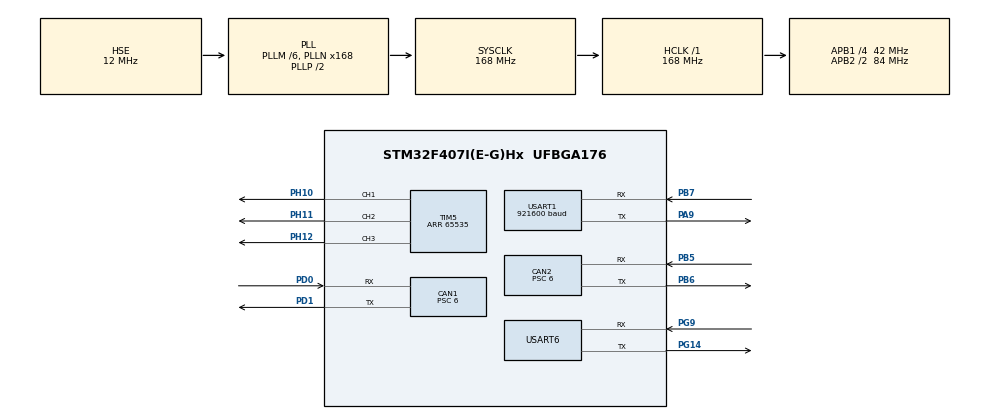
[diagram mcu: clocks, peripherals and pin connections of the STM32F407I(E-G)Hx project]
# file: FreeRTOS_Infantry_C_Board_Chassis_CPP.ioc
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CAN1.BS1=CAN_BS1_5TQ
CAN1.CalculateBaudRate=1000000
CAN1.CalculateTimeBit=1000
CAN1.CalculateTimeQuantum=142.85714285714286
CAN1.Prescaler=6
CAN2.BS1=CAN_BS1_5TQ
CAN2.CalculateBaudRate=1000000
CAN2.CalculateTimeBit=1000
CAN2.CalculateTimeQuantum=142.85714285714286
CAN2.NART=ENABLE
CAN2.Prescaler=6
Dma.Request0=USART1_RX
Dma.Request1=USART1_TX
Dma.Request2=USART6_RX
Dma.Request3=USART6_TX
Dma.USART1_RX.0.Direction=DMA_PERIPH_TO_MEMORY
Dma.USART1_RX.0.FIFOMode=DMA_FIFOMODE_DISABLE
Dma.USART1_RX.0.Instance=DMA2_Stream2
Dma.USART1_RX.0.MemDataAlignment=DMA_MDATAALIGN_BYTE
Dma.USART1_RX.0.MemInc=DMA_MINC_ENABLE
Dma.USART1_RX.0.Mode=DMA_NORMAL
Dma.USART1_RX.0.PeriphDataAlignment=DMA_PDATAALIGN_BYTE
Dma.USART1_RX.0.PeriphInc=DMA_PINC_DISABLE
Dma.USART1_RX.0.Priority=DMA_PRIORITY_LOW
Dma.USART1_TX.1.Direction=DMA_MEMORY_TO_PERIPH
Dma.USART1_TX.1.FIFOMode=DMA_FIFOMODE_DISABLE
Dma.USART1_TX.1.Instance=DMA2_Stream7
Dma.USART1_TX.1.MemDataAlignment=DMA_MDATAALIGN_BYTE
Dma.USART1_TX.1.MemInc=DMA_MINC_ENABLE
Dma.USART1_TX.1.Mode=DMA_NORMAL
Dma.USART1_TX.1.PeriphDataAlignment=DMA_PDATAALIGN_BYTE
Dma.USART1_TX.1.PeriphInc=DMA_PINC_DISABLE
Dma.USART1_TX.1.Priority=DMA_PRIORITY_LOW
Dma.USART6_RX.2.Direction=DMA_PERIPH_TO_MEMORY
Dma.USART6_RX.2.FIFOMode=DMA_FIFOMODE_DISABLE
Dma.USART6_RX.2.Instance=DMA2_Stream1
Dma.USART6_RX.2.MemDataAlignment=DMA_MDATAALIGN_BYTE
Dma.USART6_RX.2.MemInc=DMA_MINC_ENABLE
Dma.USART6_RX.2.Mode=DMA_NORMAL
Dma.USART6_RX.2.PeriphDataAlignment=DMA_PDATAALIGN_BYTE
Dma.USART6_RX.2.PeriphInc=DMA_PINC_DISABLE
Dma.USART6_RX.2.Priority=DMA_PRIORITY_LOW
Dma.USART6_TX.3.Direction=DMA_MEMORY_TO_PERIPH
Dma.USART6_TX.3.FIFOMode=DMA_FIFOMODE_DISABLE
Dma.USART6_TX.3.Instance=DMA2_Stream6
Dma.USART6_TX.3.MemDataAlignment=DMA_MDATAALIGN_BYTE
Dma.USART6_TX.3.MemInc=DMA_MINC_ENABLE
Dma.USART6_TX.3.Mode=DMA_NORMAL
Dma.USART6_TX.3.PeriphDataAlignment=DMA_PDATAALIGN_BYTE
Dma.USART6_TX.3.PeriphInc=DMA_PINC_DISABLE
Dma.USART6_TX.3.Priority=DMA_PRIORITY_LOW
FREERTOS.Tasks01=defaultTask,8,128,StartDefaultTask,Default,NULL,Dynamic,NULL,NULL;chassisTask,40,128,ChassisTask,As external,NULL,Dynamic,NULL,NULL;capacityAskTask,32,128,CapacityAskTask,As external,NULL,Dynamic,NULL,NULL;uiTask,24,128,UITask,As external,NULL,Dynamic,NULL,NULL;refereeDetect,24,128,RefereeDetectTask,As external,NULL,Dynamic,NULL,NULL;communicationTa,40,512,CommunicationTask,As external,NULL,Dynamic,NULL,NULL;errorHandleTask,16,128,ErrorHandleTask,As external,NULL,Dynamic,NULL,NULL;capacityChargeT,33,128,CapacityChargeTask,As external,NULL,Dynamic,NULL,NULL;rlsTask,16,1024,RlsTask,As external,NULL,Dynamic,NULL,NULL
Mcu.Family=STM32F4
Mcu.Name=STM32F407I(E-G)Hx
Mcu.Package=UFBGA176
NVIC.CAN1_RX0_IRQn=true\:0\:0\:true\:false\:true\:false\:true\:true\:true
NVIC.CAN2_RX0_IRQn=true\:4\:0\:true\:false\:true\:false\:true\:true\:true
NVIC.DMA2_Stream1_IRQn=true\:3\:0\:true\:false\:true\:false\:false\:true\:true
NVIC.DMA2_Stream2_IRQn=true\:4\:0\:true\:false\:true\:false\:false\:true\:true
NVIC.DMA2_Stream6_IRQn=true\:4\:0\:true\:false\:true\:false\:false\:true\:true
NVIC.DMA2_Stream7_IRQn=true\:4\:0\:true\:false\:true\:false\:false\:true\:true
NVIC.PriorityGroup=NVIC_PRIORITYGROUP_4
NVIC.TIM6_DAC_IRQn=true\:15\:0\:false\:false\:true\:false\:false\:true\:true
NVIC.TIM7_IRQn=true\:1\:0\:true\:false\:true\:false\:true\:true\:true
NVIC.TimeBase=TIM6_DAC_IRQn
NVIC.TimeBaseIP=TIM6
NVIC.USART1_IRQn=true\:4\:0\:true\:false\:true\:false\:false\:true\:true
NVIC.USART6_IRQn=true\:3\:0\:true\:false\:true\:false\:false\:true\:true
PA13.Mode=Serial_Wire
PA13.Signal=SYS_JTMS-SWDIO
PA14.Mode=Serial_Wire
PA14.Signal=SYS_JTCK-SWCLK
PA9.Mode=Asynchronous
PA9.Signal=USART1_TX
PB5.Mode=CAN_Activate
PB5.Signal=CAN2_RX
PB6.Mode=CAN_Activate
PB6.Signal=CAN2_TX
PB7.Mode=Asynchronous
PB7.Signal=USART1_RX
PD0.Mode=CAN_Activate
PD0.Signal=CAN1_RX
PD1.Mode=CAN_Activate
PD1.Signal=CAN1_TX
PG14.Mode=Asynchronous
PG14.Signal=USART6_TX
PG9.Mode=Asynchronous
PG9.Signal=USART6_RX
PH0-OSC_IN.Mode=HSE-External-Oscillator
PH0-OSC_IN.Signal=RCC_OSC_IN
PH1-OSC_OUT.Mode=HSE-External-Oscillator
PH1-OSC_OUT.Signal=RCC_OSC_OUT
PH10.Signal=S_TIM5_CH1
PH11.Signal=S_TIM5_CH2
PH12.Signal=S_TIM5_CH3
ProjectManager.HeapSize=0x200
ProjectManager.StackSize=0x400
ProjectManager.TargetToolchain=MDK-ARM V5.32
RCC.48MHZClocksFreq_Value=84000000
RCC.AHBFreq_Value=168000000
RCC.APB1CLKDivider=RCC_HCLK_DIV4
RCC.APB1Freq_Value=42000000
RCC.APB1TimFreq_Value=84000000
RCC.APB2CLKDivider=RCC_HCLK_DIV2
RCC.APB2Freq_Value=84000000
RCC.APB2TimFreq_Value=168000000
RCC.CortexFreq_Value=168000000
RCC.HCLKFreq_Value=168000000
RCC.HSE_VALUE=12000000
RCC.HSI_VALUE=16000000
RCC.LSE_VALUE=32768
RCC.PLLM=6
RCC.PLLN=168
RCC.PLLSourceVirtual=RCC_PLLSOURCE_HSE
RCC.SYSCLKFreq_VALUE=168000000
RCC.SYSCLKSource=RCC_SYSCLKSOURCE_PLLCLK
RCC.VCOOutputFreq_Value=336000000
SH.S_TIM5_CH1.0=TIM5_CH1,PWM Generation1 CH1
SH.S_TIM5_CH2.0=TIM5_CH2,PWM Generation2 CH2
SH.S_TIM5_CH3.0=TIM5_CH3,PWM Generation3 CH3
TIM5.Channel-PWM\ Generation1\ CH1=TIM_CHANNEL_1
TIM5.Channel-PWM\ Generation2\ CH2=TIM_CHANNEL_2
TIM5.Channel-PWM\ Generation3\ CH3=TIM_CHANNEL_3
TIM5.Period=65535
TIM5.Pulse-PWM\ Generation1\ CH1=10000
TIM5.Pulse-PWM\ Generation2\ CH2=10000
TIM5.Pulse-PWM\ Generation3\ CH3=10000
TIM7.Period=1000-1
TIM7.Prescaler=84-1
USART1.BaudRate=921600
USART1.VirtualMode=VM_ASYNC
USART6.VirtualMode=VM_ASYNC
VP_FREERTOS_VS_CMSIS_V2.Mode=CMSIS_V2
VP_SYS_VS_tim6.Mode=TIM6
VP_TIM5_VS_ClockSourceINT.Mode=Internal
VP_TIM7_VS_ClockSourceINT.Mode=Enable_Timer
board=custom

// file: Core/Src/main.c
/* USER CODE BEGIN Header */
/**
  ******************************************************************************
  * @file           : main.c
  * @brief          : Main program body
  ******************************************************************************
  * @attention
  *
  * Copyright (c) 2024 STMicroelectronics.
  * All rights reserved.
  *
  * This software is licensed under terms that can be found in the LICENSE file
  * in the root directory of this software component.
  * If no LICENSE file comes with this software, it is provided AS-IS.
  *
  ******************************************************************************
  */
/* USER CODE END Header */
#include "main.h"
#include "cmsis_os.h"
#include "can.h"
#include "dma.h"
#include "tim.h"
#include "usart.h"
#include "gpio.h"

void SystemClock_Config(void);
void MX_FREERTOS_Init(void);
/* USER CODE BEGIN PFP */
void init();
void MainCallBack();
/* USER CODE END PFP */

int main(void)
{

  /* MCU Configuration--------------------------------------------------------*/

  /* Reset of all peripherals, Initializes the Flash interface and the Systick. */
  HAL_Init();

  /* Configure the system clock */
  SystemClock_Config();

  /* Initialize all configured peripherals */
  MX_GPIO_Init();
  MX_DMA_Init();
  MX_CAN1_Init();
  MX_CAN2_Init();
  MX_TIM7_Init();
  MX_USART1_UART_Init();
  MX_USART6_UART_Init();
  MX_TIM5_Init();
  /* USER CODE BEGIN 2 */
  init();
  /* USER CODE END 2 */

  /* Init scheduler */
  osKernelInitialize();

  /* Call init function for freertos objects (in cmsis_os2.c) */
  MX_FREERTOS_Init();

  /* Start scheduler */
  osKernelStart();

  /* We should never get here as control is now taken by the scheduler */

  /* Infinite loop */
  while (1)
  {

  }
}

void SystemClock_Config(void)
{
  RCC_OscInitTypeDef RCC_OscInitStruct = {0};
  RCC_ClkInitTypeDef RCC_ClkInitStruct = {0};

  /** Configure the main internal regulator output voltage
  */
  __HAL_RCC_PWR_CLK_ENABLE();
  __HAL_PWR_VOLTAGESCALING_CONFIG(PWR_REGULATOR_VOLTAGE_SCALE1);

  /** Initializes the RCC Oscillators according to the specified parameters
  * in the RCC_OscInitTypeDef structure.
  */
  RCC_OscInitStruct.OscillatorType = RCC_OSCILLATORTYPE_HSE;
  RCC_OscInitStruct.HSEState = RCC_HSE_ON;
  RCC_OscInitStruct.PLL.PLLState = RCC_PLL_ON;
  RCC_OscInitStruct.PLL.PLLSource = RCC_PLLSOURCE_HSE;
  RCC_OscInitStruct.PLL.PLLM = 6;
  RCC_OscInitStruct.PLL.PLLN = 168;
  RCC_OscInitStruct.PLL.PLLP = RCC_PLLP_DIV2;
  RCC_OscInitStruct.PLL.PLLQ = 4;
  if (HAL_RCC_OscConfig(&RCC_OscInitStruct) != HAL_OK)
  {
    Error_Handler();
  }

  /** Initializes the CPU, AHB and APB buses clocks
  */
  RCC_ClkInitStruct.ClockType = RCC_CLOCKTYPE_HCLK|RCC_CLOCKTYPE_SYSCLK
                              |RCC_CLOCKTYPE_PCLK1|RCC_CLOCKTYPE_PCLK2;
  RCC_ClkInitStruct.SYSCLKSource = RCC_SYSCLKSOURCE_PLLCLK;
  RCC_ClkInitStruct.AHBCLKDivider = RCC_SYSCLK_DIV1;
  RCC_ClkInitStruct.APB1CLKDivider = RCC_HCLK_DIV4;
  RCC_ClkInitStruct.APB2CLKDivider = RCC_HCLK_DIV2;

  if (HAL_RCC_ClockConfig(&RCC_ClkInitStruct, FLASH_LATENCY_5) != HAL_OK)
  {
    Error_Handler();
  }
}

void HAL_TIM_PeriodElapsedCallback(TIM_HandleTypeDef *htim)
{
  if (htim->Instance == TIM6)
  {
    HAL_IncTick();
  }
  /* USER CODE BEGIN Callback 1 */
  else if (htim->Instance == TIM7) {
    MainCallBack();
  }
  /* USER CODE END Callback 1 */
}

void Error_Handler(void)
{
  __disable_irq();
  while (1)
  {
  }
}

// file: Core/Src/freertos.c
/* USER CODE BEGIN Header */
/**
  ******************************************************************************
  * File Name          : freertos.c
  * Description        : Code for freertos applications
  ******************************************************************************
  * @attention
  *
  * Copyright (c) 2024 STMicroelectronics.
  * All rights reserved.
  *
  * This software is licensed under terms that can be found in the LICENSE file
  * in the root directory of this software component.
  * If no LICENSE file comes with this software, it is provided AS-IS.
  *
  ******************************************************************************
  */
/* USER CODE END Header */

#include "FreeRTOS.h"
#include "task.h"
#include "main.h"
#include "cmsis_os.h"

/* Definitions for defaultTask */
osThreadId_t defaultTaskHandle;
const osThreadAttr_t defaultTask_attributes = {
  .name = "defaultTask",
  .stack_size = 128 * 4,
  .priority = (osPriority_t) osPriorityLow,
};
/* Definitions for chassisTask */
osThreadId_t chassisTaskHandle;
const osThreadAttr_t chassisTask_attributes = {
  .name = "chassisTask",
  .stack_size = 1024 * 4,
  .priority = (osPriority_t) osPriorityNormal,
};
/* Definitions for capacityAskTask */
osThreadId_t capacityAskTaskHandle;
const osThreadAttr_t capacityAskTask_attributes = {
  .name = "capacityAskTask",
  .stack_size = 128 * 4,
  .priority = (osPriority_t) osPriorityAboveNormal,
};
/* Definitions for uiTask */
osThreadId_t uiTaskHandle;
const osThreadAttr_t uiTask_attributes = {
  .name = "uiTask",
  .stack_size = 128 * 4,
  .priority = (osPriority_t) osPriorityNormal,
};
/* Definitions for refereeDetect */
osThreadId_t refereeDetectHandle;
const osThreadAttr_t refereeDetect_attributes = {
  .name = "refereeDetect",
  .stack_size = 128 * 4,
  .priority = (osPriority_t) osPriorityNormal,
};
/* Definitions for communicationTa */
osThreadId_t communicationTaHandle;
const osThreadAttr_t communicationTa_attributes = {
  .name = "communicationTa",
  .stack_size = 1024 * 4,
  .priority = (osPriority_t) osPriorityNormal,
};
/* Definitions for errorHandleTask */
osThreadId_t errorHandleTaskHandle;
const osThreadAttr_t errorHandleTask_attributes = {
  .name = "errorHandleTask",
  .stack_size = 128 * 4,
  .priority = (osPriority_t) osPriorityBelowNormal,
};
/* Definitions for capacityChargeT */
osThreadId_t capacityChargeTHandle;
const osThreadAttr_t capacityChargeT_attributes = {
  .name = "capacityChargeT",
  .stack_size = 128 * 4,
  .priority = (osPriority_t) osPriorityAboveNormal1,
};
/* Definitions for rlsTask */
osThreadId_t rlsTaskHandle;
const osThreadAttr_t rlsTask_attributes = {
  .name = "rlsTask",
  .stack_size = 1024 * 4,
  .priority = (osPriority_t) osPriorityBelowNormal,
};

void StartDefaultTask(void *argument);
extern void ChassisTask(void *argument);
extern void CapacityAskTask(void *argument);
//extern void UITask(void *argument);
//extern void RefereeDetectTask(void *argument);
extern void CommunicationTask(void *argument);
extern void ErrorHandleTask(void *argument);
extern void CapacityChargeTask(void *argument);
extern void RlsTask(void *argument);

void MX_FREERTOS_Init(void); /* (MISRA C 2004 rule 8.1) */

void MX_FREERTOS_Init(void) {

  /* Create the thread(s) */
  /* creation of defaultTask */
  defaultTaskHandle = osThreadNew(StartDefaultTask, NULL, &defaultTask_attributes);

  /* creation of chassisTask */
  chassisTaskHandle = osThreadNew(ChassisTask, NULL, &chassisTask_attributes);

  /* creation of capacityAskTask */
  capacityAskTaskHandle = osThreadNew(CapacityAskTask, NULL, &capacityAskTask_attributes);

  /* creation of uiTask */
  //uiTaskHandle = osThreadNew(UITask, NULL, &uiTask_attributes);

  /* creation of refereeDetect */
  //refereeDetectHandle = osThreadNew(RefereeDetectTask, NULL, &refereeDetect_attributes);

  /* creation of communicationTa */
  communicationTaHandle = osThreadNew(CommunicationTask, NULL, &communicationTa_attributes);

  /* creation of errorHandleTask */
  errorHandleTaskHandle = osThreadNew(ErrorHandleTask, NULL, &errorHandleTask_attributes);

  /* creation of capacityChargeT */
  capacityChargeTHandle = osThreadNew(CapacityChargeTask, NULL, &capacityChargeT_attributes);

  /* creation of rlsTask */
  rlsTaskHandle = osThreadNew(RlsTask, NULL, &rlsTask_attributes);

}

void StartDefaultTask(void *argument)
{
  /* USER CODE BEGIN StartDefaultTask */
  /* Infinite loop */
  for(;;)
  {
    osDelay(5);
  }
  /* USER CODE END StartDefaultTask */
}
